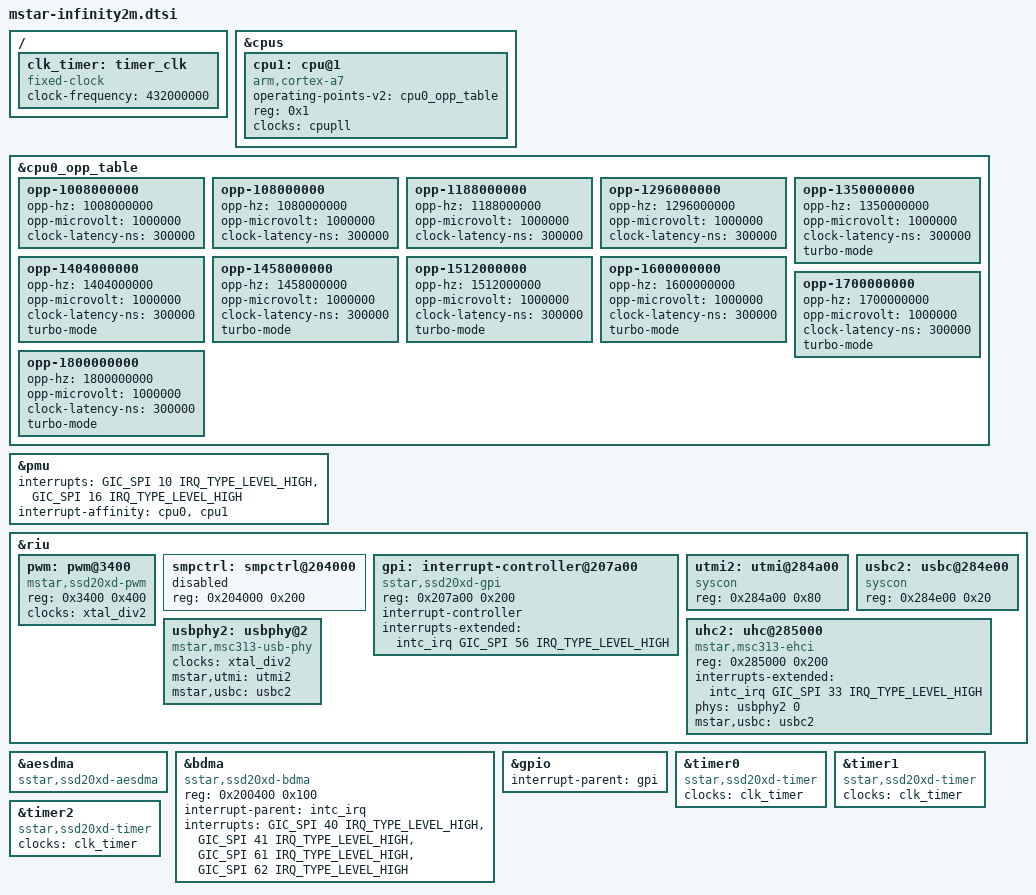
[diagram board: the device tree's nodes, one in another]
// SPDX-License-Identifier: GPL-2.0-or-later
/*
 * Copyright (c) 2020 thingy.jp.
 * Author: Daniel Palmer <daniel@thingy.jp>
 */

#include "mstar-infinity.dtsi"

/ {
	clk_timer: timer_clk {
		#clock-cells = <0>;
		compatible = "fixed-clock";
		clock-frequency = <432000000>;
	};
};

&cpus {
	cpu1: cpu@1 {
		device_type = "cpu";
		compatible = "arm,cortex-a7";
		operating-points-v2 = <&cpu0_opp_table>;
		reg = <0x1>;
		clocks = <&cpupll>;
		clock-names = "cpuclk";
	};
};

&cpu0_opp_table {
	opp-1008000000 {
		opp-hz = /bits/ 64 <1008000000>;
		opp-microvolt = <1000000>;
		clock-latency-ns = <300000>;
	};

	opp-108000000 {
		opp-hz = /bits/ 64 <1080000000>;
		opp-microvolt = <1000000>;
		clock-latency-ns = <300000>;
	};

	opp-1188000000 {
		opp-hz = /bits/ 64 <1188000000>;
		opp-microvolt = <1000000>;
		clock-latency-ns = <300000>;
	};

	opp-1296000000 {
		opp-hz = /bits/ 64 <1296000000>;
		opp-microvolt = <1000000>;
		clock-latency-ns = <300000>;
	};

	/* Overclock. Stable upto 1.8GHz */
	opp-1350000000 {
		opp-hz = /bits/ 64 <1350000000>;
		opp-microvolt = <1000000>;
		clock-latency-ns = <300000>;
		turbo-mode;
	};

	opp-1404000000 {
		opp-hz = /bits/ 64 <1404000000>;
		opp-microvolt = <1000000>;
		clock-latency-ns = <300000>;
		turbo-mode;
	};

	opp-1458000000 {
		opp-hz = /bits/ 64 <1458000000>;
		opp-microvolt = <1000000>;
		clock-latency-ns = <300000>;
		turbo-mode;
	};

	opp-1512000000 {
		opp-hz = /bits/ 64 <1512000000>;
		opp-microvolt = <1000000>;
		clock-latency-ns = <300000>;
		turbo-mode;
	};

	opp-1600000000 {
		opp-hz = /bits/ 64 <1600000000>;
		opp-microvolt = <1000000>;
		clock-latency-ns = <300000>;
		turbo-mode;
	};

	opp-1700000000 {
		opp-hz = /bits/ 64 <1700000000>;
		opp-microvolt = <1000000>;
		clock-latency-ns = <300000>;
		turbo-mode;
	};

	opp-1800000000 {
		opp-hz = /bits/ 64 <1800000000>;
		opp-microvolt = <1000000>;
		clock-latency-ns = <300000>;
		turbo-mode;
	};
};

&pmu {
		interrupts = <GIC_SPI 10 IRQ_TYPE_LEVEL_HIGH>,
			     <GIC_SPI 16 IRQ_TYPE_LEVEL_HIGH>;
		interrupt-affinity = <&cpu0>, <&cpu1>;
};

&riu {
	pwm: pwm@3400 {
		compatible = "mstar,ssd20xd-pwm";
		reg = <0x3400 0x400>;
		#pwm-cells = <2>;
		clocks = <&xtal_div2>;
	};

	//start address for second cpu
	//0x1F20404C
	//0x1F204050
	//0x1F204058 -- unlock

	smpctrl: smpctrl@204000 {
		reg = <0x204000 0x200>;
		status = "disabled";
	};

	gpi: interrupt-controller@207a00 {
		compatible = "sstar,ssd20xd-gpi";
		reg = <0x207a00 0x200>;
		#interrupt-cells = <2>;
		interrupt-controller;
		interrupts-extended = <&intc_irq GIC_SPI 56 IRQ_TYPE_LEVEL_HIGH>;
	};

	utmi2: utmi@284a00 {
		compatible = "syscon";
		reg = <0x284a00 0x80>;
	};

	usbc2: usbc@284e00 {
		compatible = "syscon";
		reg = <0x284e00 0x20>;
	};

	usbphy2: usbphy@2 {
		#phy-cells = <1>;
		compatible = "mstar,msc313-usb-phy";
		clocks = <&xtal_div2>;
		mstar,utmi = <&utmi2>;
		mstar,usbc = <&usbc2>;
		//status = "disabled";
	};

	uhc2: uhc@285000 {
		compatible = "mstar,msc313-ehci";
		reg = <0x285000 0x200>;
		interrupts-extended = <&intc_irq GIC_SPI 33 IRQ_TYPE_LEVEL_HIGH>;
		phys = <&usbphy2 0>;
		phy-names = "usb";
		mstar,usbc = <&usbc2>;
		//status = "disabled";
	};
};

&aesdma {
	compatible = "sstar,ssd20xd-aesdma";
};

&bdma {
	compatible = "sstar,ssd20xd-bdma";
	reg = <0x200400 0x100>;
	interrupt-parent = <&intc_irq>;
	interrupts = <GIC_SPI 40 IRQ_TYPE_LEVEL_HIGH>,
		     <GIC_SPI 41 IRQ_TYPE_LEVEL_HIGH>,
		     <GIC_SPI 61 IRQ_TYPE_LEVEL_HIGH>,
		     <GIC_SPI 62 IRQ_TYPE_LEVEL_HIGH>;
};

&gpio {
	interrupt-parent = <&gpi>;
};

&timer0 {
	compatible = "sstar,ssd20xd-timer";
	clocks = <&clk_timer>;
};

&timer1 {
	compatible = "sstar,ssd20xd-timer";
	clocks = <&clk_timer>;
};

&timer2 {
	compatible = "sstar,ssd20xd-timer";
	clocks = <&clk_timer>;
};
